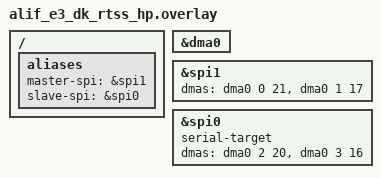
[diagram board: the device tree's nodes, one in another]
/* Copyright (C) 2024 Alif Semiconductor - All Rights Reserved.
 * Use, distribution and modification of this code is permitted under the
 * terms stated in the Alif Semiconductor Software License Agreement
 *
 * You should have received a copy of the Alif Semiconductor Software
 * License Agreement with this file. If not, please write to:
 * contact@alifsemi.com, or visit: https://alifsemi.com/license
 *
 */

/* setting SPI1 as master and SPI0 instance as slave.
 *
 */

/ {
	aliases {
		master-spi = &spi1;
		slave-spi = &spi0;
	};
};

&dma0 {
	status = "okay";
};

&spi1 {
	status = "okay";
	dmas = <&dma0 0 21>, <&dma0 1 17>;
	dma-names = "txdma", "rxdma";
};

&spi0 {
	status = "okay";
	serial-target;
	dmas = <&dma0 2 20>, <&dma0 3 16>;
	dma-names = "txdma", "rxdma";
};
